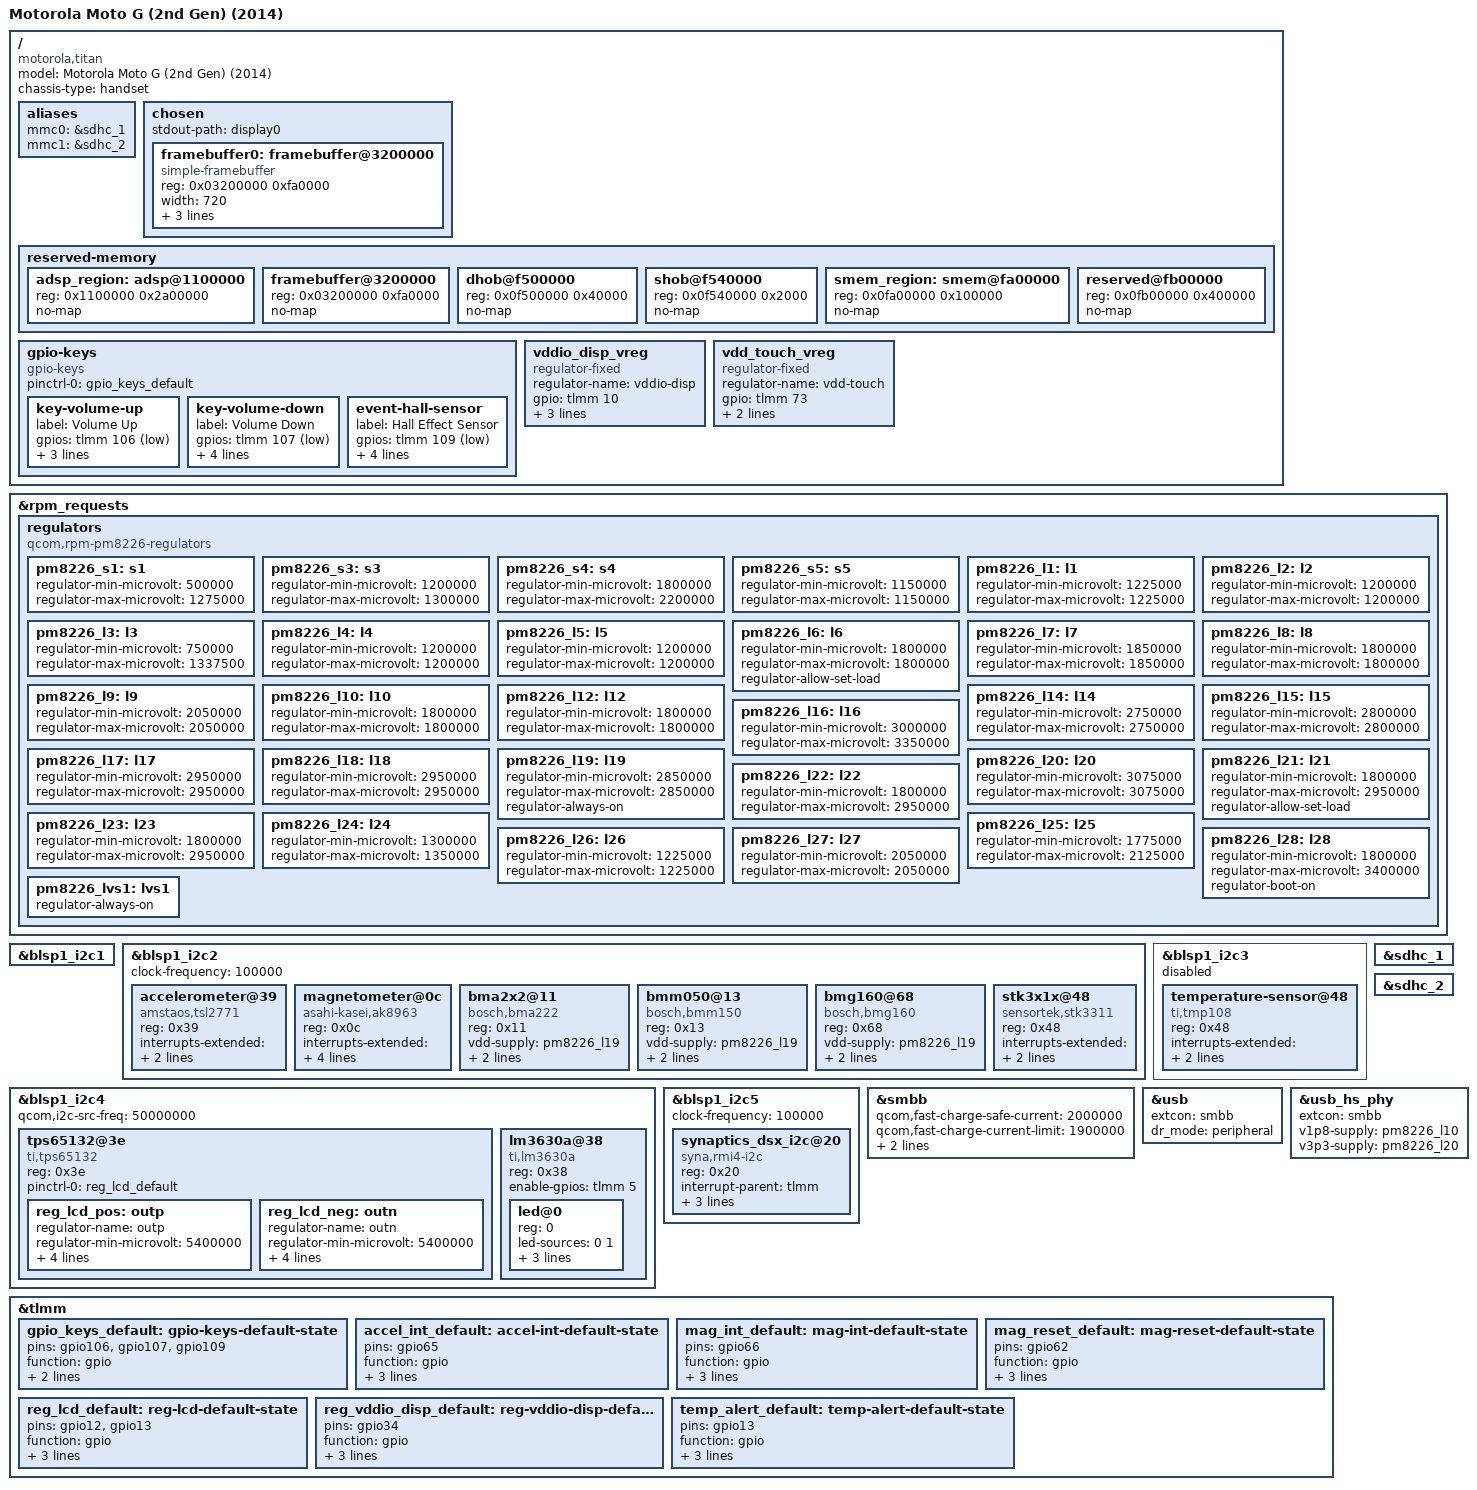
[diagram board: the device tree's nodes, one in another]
// SPDX-License-Identifier: BSD-3-Clause

/dts-v1/;

#include "qcom-msm8226.dtsi"
#include "pm8226.dtsi"
#include <dt-bindings/input/input.h>
#include <dt-bindings/interrupt-controller/irq.h>
#include <dt-bindings/arm/qcom,ids.h>

/delete-node/ &smem_region;
/delete-node/ &adsp_region;

/ {
	model = "Motorola Moto G (2nd Gen) (2014)";
	compatible = "motorola,titan", "qcom,msm8226";
	chassis-type = "handset";

	aliases {
		mmc0 = &sdhc_1; /* SDC1 eMMC slot */
		mmc1 = &sdhc_2; /* SDC2 SD card slot */
	};

	chosen {
		#address-cells = <1>;
		#size-cells = <1>;
		ranges;

		stdout-path = "display0";

		framebuffer0: framebuffer@3200000 {
			compatible = "simple-framebuffer";
			reg = <0x03200000 0xfa0000>;
			width = <720>;
			height = <1280>;
			stride = <(720 * 3)>;
			format = "r8g8b8";
		};
	};

	reserved-memory {
		#address-cells = <1>;
		#size-cells = <1>;
		ranges;

		adsp_region: adsp@1100000 {
			reg = <0x1100000 0x2a00000>;
			no-map;
		};

		framebuffer@3200000 {
			reg = <0x03200000 0xfa0000>;
			no-map;
		};

		dhob@f500000 {
			reg = <0x0f500000 0x40000>;
			no-map;
		};

		shob@f540000 {
			reg = <0x0f540000 0x2000>;
			no-map;
		};

		smem_region: smem@fa00000 {
			reg = <0x0fa00000 0x100000>;
			no-map;
		};

		/* Actually <0x0fa00000 0x500000>, but first 100000 is smem */
		reserved@fb00000 {
			reg = <0x0fb00000 0x400000>;
			no-map;
		};
	};

	gpio-keys {
		compatible = "gpio-keys";

		pinctrl-0 = <&gpio_keys_default>;
		pinctrl-names = "default";

		key-volume-up {
			label = "Volume Up";
			gpios = <&tlmm 106 GPIO_ACTIVE_LOW>;
			linux,input-type = <EV_KEY>;
			linux,code = <KEY_VOLUMEUP>;
			debounce-interval = <15>;
		};

		key-volume-down {
			label = "Volume Down";
			gpios = <&tlmm 107 GPIO_ACTIVE_LOW>;
			linux,input-type = <EV_KEY>;
			linux,code = <KEY_VOLUMEDOWN>;
			gpio-key,wakeup;
			debounce-interval = <15>;
		};

		event-hall-sensor {
			label = "Hall Effect Sensor";
			gpios = <&tlmm 109 GPIO_ACTIVE_LOW>;
			linux,input-type = <EV_SW>;
			linux,code = <KEY_RESERVED>;
			gpio-key,wakeup;
			debounce-interval = <15>;
		};
	};

	vddio_disp_vreg: vddio_disp_vreg {
		compatible = "regulator-fixed";
		regulator-name = "vddio-disp";
		gpio = <&tlmm 10 GPIO_ACTIVE_HIGH>;
		startup-delay-us = <300>;
		enable-active-high;
		regulator-boot-on;
	};

	vdd_touch_vreg: vdd_touch_vreg {
		compatible = "regulator-fixed";
		regulator-name = "vdd-touch";
		gpio = <&tlmm 73 GPIO_ACTIVE_HIGH>;
		startup-delay-us = <300>;
		enable-active-high;
	};
};

&rpm_requests {
	regulators {
		compatible = "qcom,rpm-pm8226-regulators";

		pm8226_s1: s1 {
			regulator-min-microvolt = <500000>;
			regulator-max-microvolt = <1275000>;
		};

		pm8226_s3: s3 {
			regulator-min-microvolt = <1200000>;
			regulator-max-microvolt = <1300000>;
		};

		pm8226_s4: s4 {
			regulator-min-microvolt = <1800000>;
			regulator-max-microvolt = <2200000>;
		};

		pm8226_s5: s5 {
			regulator-min-microvolt = <1150000>;
			regulator-max-microvolt = <1150000>;
		};

		pm8226_l1: l1 {
			regulator-min-microvolt = <1225000>;
			regulator-max-microvolt = <1225000>;
		};

		pm8226_l2: l2 {
			regulator-min-microvolt = <1200000>;
			regulator-max-microvolt = <1200000>;
		};

		pm8226_l3: l3 {
			regulator-min-microvolt = <750000>;
			regulator-max-microvolt = <1337500>;
		};

		pm8226_l4: l4 {
			regulator-min-microvolt = <1200000>;
			regulator-max-microvolt = <1200000>;
		};

		pm8226_l5: l5 {
			regulator-min-microvolt = <1200000>;
			regulator-max-microvolt = <1200000>;
		};

		pm8226_l6: l6 {
			regulator-min-microvolt = <1800000>;
			regulator-max-microvolt = <1800000>;
			regulator-allow-set-load;
		};

		pm8226_l7: l7 {
			regulator-min-microvolt = <1850000>;
			regulator-max-microvolt = <1850000>;
		};

		pm8226_l8: l8 {
			regulator-min-microvolt = <1800000>;
			regulator-max-microvolt = <1800000>;
		};

		pm8226_l9: l9 {
			regulator-min-microvolt = <2050000>;
			regulator-max-microvolt = <2050000>;
		};

		pm8226_l10: l10 {
			regulator-min-microvolt = <1800000>;
			regulator-max-microvolt = <1800000>;
		};

		pm8226_l12: l12 {
			regulator-min-microvolt = <1800000>;
			regulator-max-microvolt = <1800000>;
		};

		pm8226_l14: l14 {
			regulator-min-microvolt = <2750000>;
			regulator-max-microvolt = <2750000>;
		};

		pm8226_l15: l15 {
			regulator-min-microvolt = <2800000>;
			regulator-max-microvolt = <2800000>;
		};

		pm8226_l16: l16 {
			regulator-min-microvolt = <3000000>;
			regulator-max-microvolt = <3350000>;
		};

		pm8226_l17: l17 {
			regulator-min-microvolt = <2950000>;
			regulator-max-microvolt = <2950000>;
		};

		pm8226_l18: l18 {
			regulator-min-microvolt = <2950000>;
			regulator-max-microvolt = <2950000>;
		};

		pm8226_l19: l19 {
			regulator-min-microvolt = <2850000>;
			regulator-max-microvolt = <2850000>;
			regulator-always-on;
		};

		pm8226_l20: l20 {
			regulator-min-microvolt = <3075000>;
			regulator-max-microvolt = <3075000>;
		};

		pm8226_l21: l21 {
			regulator-min-microvolt = <1800000>;
			regulator-max-microvolt = <2950000>;
			regulator-allow-set-load;
		};

		pm8226_l22: l22 {
			regulator-min-microvolt = <1800000>;
			regulator-max-microvolt = <2950000>;
		};

		pm8226_l23: l23 {
			regulator-min-microvolt = <1800000>;
			regulator-max-microvolt = <2950000>;
		};

		pm8226_l24: l24 {
			regulator-min-microvolt = <1300000>;
			regulator-max-microvolt = <1350000>;
		};

		pm8226_l25: l25 {
			regulator-min-microvolt = <1775000>;
			regulator-max-microvolt = <2125000>;
		};

		pm8226_l26: l26 {
			regulator-min-microvolt = <1225000>;
			regulator-max-microvolt = <1225000>;
		};

		pm8226_l27: l27 {
			regulator-min-microvolt = <2050000>;
			regulator-max-microvolt = <2050000>;
		};

		pm8226_l28: l28 {
			regulator-min-microvolt = <1800000>;
			regulator-max-microvolt = <3400000>;
			regulator-boot-on;
		};

		pm8226_lvs1: lvs1 {
			/* Pull-up for I2C lines */
			regulator-always-on;
		};
	};
};

&blsp1_i2c1 {
	status = "okay";
};

&blsp1_i2c2 {
	clock-frequency = <100000>;
	status = "okay";

	accelerometer@39 {
		compatible = "amstaos,tsl2771";
		reg = <0x39>;
		interrupts-extended = <&tlmm 65 IRQ_TYPE_EDGE_FALLING>;
		vdd-supply = <&pm8226_l19>;
	};

	magnetometer@0c {
		compatible = "asahi-kasei,ak8963";
		reg = <0x0c>;
		interrupts-extended = <&tlmm 38 IRQ_TYPE_EDGE_FALLING>;
		reset-gpios = <&tlmm 62 GPIO_ACTIVE_LOW>;
		vdd-supply = <&pm8226_l19>;
		pinctrl-0 = <&mag_int_default &mag_reset_default>;
		pinctrl-names = "default";
	};

	bma2x2@11 {
		compatible = "bosch,bma222";
		reg = <0x11>;
		vdd-supply = <&pm8226_l19>;
		interrupts-extended = <&tlmm 63 IRQ_TYPE_LEVEL_LOW>; /* IRQ */
	};

	bmm050@13 {
		compatible = "bosch,bmm150";
		reg = <0x13>;
		vdd-supply = <&pm8226_l19>;
		interrupts-extended = <&tlmm 66 IRQ_TYPE_LEVEL_LOW>; /* IRQ */
	};

	bmg160@68 {
		compatible = "bosch,bmg160";
		reg = <0x68>;
		vdd-supply = <&pm8226_l19>;
		interrupts-extended = <&tlmm 64 IRQ_TYPE_LEVEL_LOW>; /* IRQ */
	};

	stk3x1x@48 {
		compatible = "sensortek,stk3311";
		reg = <0x48>;
		interrupts-extended = <&tlmm 65 IRQ_TYPE_LEVEL_LOW>; /* IRQ */
		proximity-near-level = <25>;
	};
};

&blsp1_i2c3 {
	status = "disabled";
	/delete-node/ tps65132@3e;

	temperature-sensor@48 {
		compatible = "ti,tmp108";
		reg = <0x48>;
		interrupts-extended = <&tlmm 13 IRQ_TYPE_LEVEL_LOW>;
		pinctrl-0 = <&temp_alert_default>;
		pinctrl-names = "default";
		#thermal-sensor-cells = <0>;
	};
};

&blsp1_i2c4 {
	qcom,i2c-src-freq = <50000000>;
		tps65132@3e {
			compatible = "ti,tps65132";
			reg = <0x3e>;
			pinctrl-0 = <&reg_lcd_default>;
			pinctrl-names = "default";

			reg_lcd_pos: outp {
				regulator-name = "outp";
				regulator-min-microvolt = <5400000>;
				regulator-max-microvolt = <5400000>;
				regulator-active-discharge = <1>;
				regulator-boot-on;
				enable-gpios = <&tlmm 31 GPIO_ACTIVE_HIGH>;
			};

			reg_lcd_neg: outn {
				regulator-name = "outn";
				regulator-min-microvolt = <5400000>;
				regulator-max-microvolt = <5400000>;
				regulator-active-discharge = <1>;
				regulator-boot-on;
				enable-gpios = <&tlmm 33 GPIO_ACTIVE_HIGH>;
			};
		};

		lm3630a@38 {
			compatible = "ti,lm3630a";
			reg = <0x38>;
			enable-gpios = <&tlmm 5 GPIO_ACTIVE_HIGH>;
			status = "okay";

			#address-cells = <1>;
			#size-cells = <0>;

			led@0 {
				reg = <0>;
				led-sources = <0 1>;
				label = "lcd-backlight"; /* Not sure yet*/
				default-brightness = <200>;
				max-brightness = <255>;
			};
		};
};

&blsp1_i2c5 {
	clock-frequency = <100000>;
	status = "okay";

	synaptics_dsx_i2c@20 {
		compatible = "syna,rmi4-i2c";
		reg = <0x20>;
		interrupt-parent = <&tlmm>;
		interrupts = <17 IRQ_TYPE_EDGE_FALLING>;
		reset-gpios = <&tlmm 16 GPIO_ACTIVE_LOW>;
		vdd-supply = <&vdd_touch_vreg>;
	};
};

&sdhc_1 {
	status = "okay";
};

&sdhc_2 {
	status = "okay";
};

&smbb {
	qcom,fast-charge-safe-current = <2000000>;
	qcom,fast-charge-current-limit = <1900000>;
	qcom,fast-charge-safe-voltage = <4400000>;
	qcom,minimum-input-voltage = <4300000>;

	status = "okay";
};

&usb {
	extcon = <&smbb>;
	dr_mode = "peripheral";
	status = "okay";
};

&usb_hs_phy {
	extcon = <&smbb>;
	v1p8-supply = <&pm8226_l10>;
	v3p3-supply = <&pm8226_l20>;
};

&tlmm {
	gpio_keys_default: gpio-keys-default-state {
		pins = "gpio106", "gpio107", "gpio109";
		function = "gpio";
		drive-strength = <2>;
		bias-pull-up;
	};

	accel_int_default: accel-int-default-state {
		pins = "gpio65";
		function = "gpio";
		drive-strength = <2>;
		bias-disable;
		output-disable;
	};

	mag_int_default: mag-int-default-state {
		pins = "gpio66";
		function = "gpio";
		drive-strength = <2>;
		bias-disable;
		output-disable;
	};

	mag_reset_default: mag-reset-default-state {
		pins = "gpio62";
		function = "gpio";
		drive-strength = <2>;
		bias-disable;
		output-high;
	};

	reg_lcd_default: reg-lcd-default-state {
		pins = "gpio12", "gpio13";
		function = "gpio";
		drive-strength = <2>;
		bias-disable;
		output-high;
	};

	reg_vddio_disp_default: reg-vddio-disp-default-state {
		pins = "gpio34";
		function = "gpio";
		drive-strength = <2>;
		bias-disable;
		output-high;
	};

	temp_alert_default: temp-alert-default-state {
		pins = "gpio13";
		function = "gpio";
		drive-strength = <2>;
		bias-disable;
		output-disable;
	};
};

